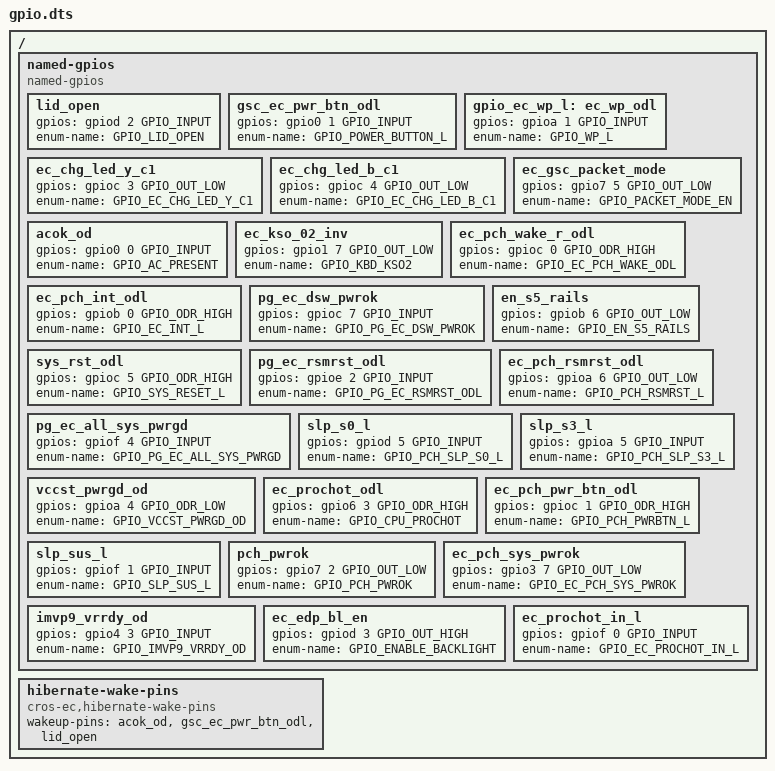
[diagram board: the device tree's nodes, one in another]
/* Copyright 2021 The Chromium OS Authors. All rights reserved.
 * Use of this source code is governed by a BSD-style license that can be
 * found in the LICENSE file.
 */

/ {
	named-gpios {
		compatible = "named-gpios";

		lid_open: lid_open {
			gpios = <&gpiod 2 GPIO_INPUT>;
			enum-name = "GPIO_LID_OPEN";
		};

		gsc_ec_pwr_btn_odl: gsc_ec_pwr_btn_odl {
			gpios = <&gpio0 1 GPIO_INPUT>;
			enum-name = "GPIO_POWER_BUTTON_L";
		};

		gpio_ec_wp_l: ec_wp_odl {
			#gpio-cells = <0>;
			gpios = <&gpioa 1 GPIO_INPUT>;
			enum-name = "GPIO_WP_L";
		};

		ec_chg_led_y_c1 {
			gpios = <&gpioc 3 GPIO_OUT_LOW>;
			enum-name = "GPIO_EC_CHG_LED_Y_C1";
		};

		ec_chg_led_b_c1 {
			gpios = <&gpioc 4 GPIO_OUT_LOW>;
			enum-name = "GPIO_EC_CHG_LED_B_C1";
		};

		ec_gsc_packet_mode {
			gpios = <&gpio7 5 GPIO_OUT_LOW>;
			enum-name = "GPIO_PACKET_MODE_EN";
		};
		acok_od: acok_od {
			gpios = <&gpio0 0 GPIO_INPUT>;
			enum-name = "GPIO_AC_PRESENT";
		};
		ec_kso_02_inv {
			gpios = <&gpio1 7 GPIO_OUT_LOW>;
			enum-name = "GPIO_KBD_KSO2";
		};
		ec_pch_wake_r_odl {
			gpios = <&gpioc 0 GPIO_ODR_HIGH>;
			enum-name = "GPIO_EC_PCH_WAKE_ODL";
		};
		ec_pch_int_odl {
			gpios = <&gpiob 0 GPIO_ODR_HIGH>;
			enum-name = "GPIO_EC_INT_L";
		};
		pg_ec_dsw_pwrok {
			gpios = <&gpioc 7 GPIO_INPUT>;
			enum-name = "GPIO_PG_EC_DSW_PWROK";
		};
		en_s5_rails {
			gpios = <&gpiob 6 GPIO_OUT_LOW>;
			enum-name = "GPIO_EN_S5_RAILS";
		};
		sys_rst_odl {
			gpios = <&gpioc 5 GPIO_ODR_HIGH>;
			enum-name = "GPIO_SYS_RESET_L";
		};
		pg_ec_rsmrst_odl {
			gpios = <&gpioe 2 GPIO_INPUT>;
			enum-name = "GPIO_PG_EC_RSMRST_ODL";
		};
		ec_pch_rsmrst_odl {
			gpios = <&gpioa 6 GPIO_OUT_LOW>;
			enum-name = "GPIO_PCH_RSMRST_L";
		};
		pg_ec_all_sys_pwrgd {
			gpios = <&gpiof 4 GPIO_INPUT>;
			enum-name = "GPIO_PG_EC_ALL_SYS_PWRGD";
		};
		slp_s0_l {
			gpios = <&gpiod 5 GPIO_INPUT>;
			enum-name = "GPIO_PCH_SLP_S0_L";
		};
		slp_s3_l {
			gpios = <&gpioa 5 GPIO_INPUT>;
			enum-name = "GPIO_PCH_SLP_S3_L";
		};
		vccst_pwrgd_od {
			gpios = <&gpioa 4 GPIO_ODR_LOW>;
			enum-name = "GPIO_VCCST_PWRGD_OD";
		};
		ec_prochot_odl {
			gpios = <&gpio6 3 GPIO_ODR_HIGH>;
			enum-name = "GPIO_CPU_PROCHOT";
		};
		ec_pch_pwr_btn_odl {
			gpios = <&gpioc 1 GPIO_ODR_HIGH>;
			enum-name = "GPIO_PCH_PWRBTN_L";
		};
		slp_sus_l {
			gpios = <&gpiof 1 GPIO_INPUT>;
			enum-name = "GPIO_SLP_SUS_L";
		};
		pch_pwrok {
			gpios = <&gpio7 2 GPIO_OUT_LOW>;
			enum-name = "GPIO_PCH_PWROK";
		};
		ec_pch_sys_pwrok {
			gpios = <&gpio3 7 GPIO_OUT_LOW>;
			enum-name = "GPIO_EC_PCH_SYS_PWROK";
		};
		imvp9_vrrdy_od {
			gpios = <&gpio4 3 GPIO_INPUT>;
			enum-name = "GPIO_IMVP9_VRRDY_OD";
		};
		ec_edp_bl_en {
			gpios = <&gpiod 3 GPIO_OUT_HIGH>;
			enum-name = "GPIO_ENABLE_BACKLIGHT";
		};
		ec_prochot_in_l {
			gpios = <&gpiof 0 GPIO_INPUT>;
			enum-name = "GPIO_EC_PROCHOT_IN_L";
		};
	};

	hibernate-wake-pins {
		compatible = "cros-ec,hibernate-wake-pins";
		wakeup-pins = <
			&acok_od
			&gsc_ec_pwr_btn_odl
			&lid_open
		>;
	};
};
